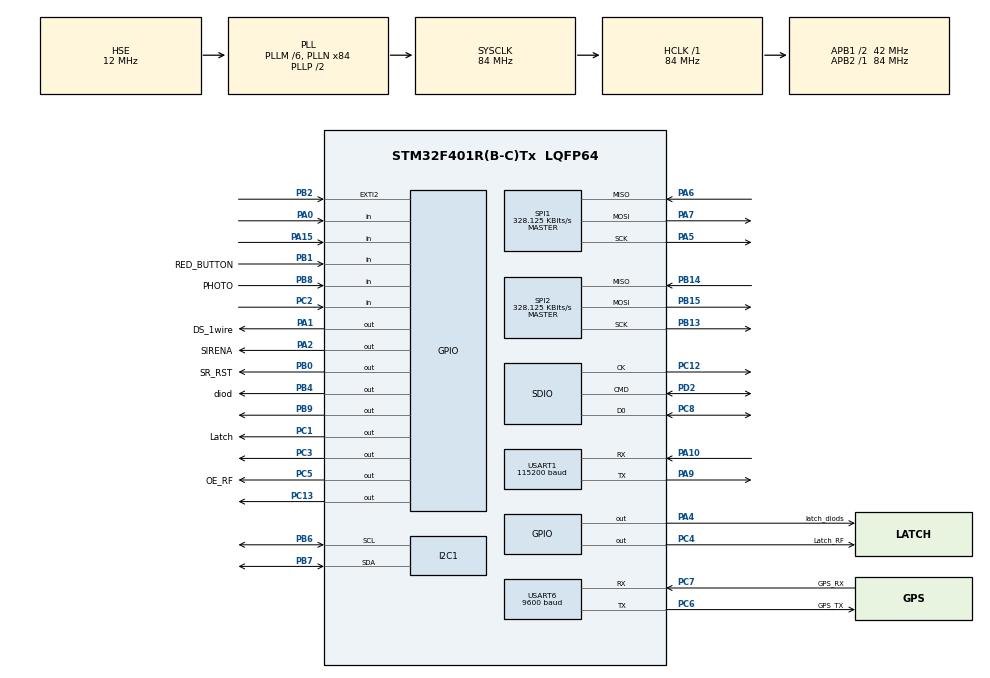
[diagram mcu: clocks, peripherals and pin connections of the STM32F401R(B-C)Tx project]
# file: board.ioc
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FATFS.BSP.number=1
FATFS._FS_LOCK=5
FATFS._USE_LFN=1
FATFS0.BSP.STBoard=false
FATFS0.BSP.api=Unknown
FATFS0.BSP.instance=PA15
FATFS0.BSP.ip=GPIO
FATFS0.BSP.mode=Input
FATFS0.BSP.name=Detect_SDIO
FATFS0.BSP.solution=PA15
Mcu.Family=STM32F4
Mcu.Name=STM32F401R(B-C)Tx
Mcu.Package=LQFP64
NVIC.PriorityGroup=NVIC_PRIORITYGROUP_4
NVIC.USART6_IRQn=true\:0\:0\:false\:false\:true\:true\:true\:true
PA0-WKUP.Signal=GPIO_Input
PA1.GPIO_Label=DS_1wire
PA1.Signal=GPIO_Output
PA10.Mode=Asynchronous
PA10.Signal=USART1_RX
PA13.Mode=Serial_Wire
PA13.Signal=SYS_JTMS-SWDIO
PA14.Mode=Serial_Wire
PA14.Signal=SYS_JTCK-SWCLK
PA15.GPIO_PuPd=GPIO_PULLUP
PA15.Signal=GPIO_Input
PA2.GPIO_Label=SIRENA
PA2.Signal=GPIO_Output
PA4.GPIO_Label=latch_diods
PA4.Signal=GPIO_Output
PA5.Mode=Full_Duplex_Master
PA5.Signal=SPI1_SCK
PA6.Mode=Full_Duplex_Master
PA6.Signal=SPI1_MISO
PA7.Mode=Full_Duplex_Master
PA7.Signal=SPI1_MOSI
PA9.Mode=Asynchronous
PA9.Signal=USART1_TX
PB0.GPIO_Label=SR_RST
PB0.PinState=GPIO_PIN_SET
PB0.Signal=GPIO_Output
PB1.GPIO_Label=RED_BUTTON
PB1.GPIO_PuPd=GPIO_PULLUP
PB1.Signal=GPIO_Input
PB13.Mode=Full_Duplex_Master
PB13.Signal=SPI2_SCK
PB14.Mode=Full_Duplex_Master
PB14.Signal=SPI2_MISO
PB15.Mode=Full_Duplex_Master
PB15.Signal=SPI2_MOSI
PB2.Signal=GPXTI2
PB4.GPIO_Label=diod
PB4.Signal=GPIO_Output
PB6.Mode=I2C
PB6.Signal=I2C1_SCL
PB7.Mode=I2C
PB7.Signal=I2C1_SDA
PB8.GPIO_Label=PHOTO
PB8.Signal=GPIO_Input
PB9.Signal=GPIO_Output
PC1.GPIO_Label=Latch
PC1.Signal=GPIO_Output
PC12.Mode=SD_1_bit
PC12.Signal=SDIO_CK
PC13-ANTI_TAMP.Signal=GPIO_Output
PC2.Signal=GPIO_Input
PC3.GPIO_ModeDefaultOutputPP=GPIO_MODE_OUTPUT_PP
PC3.GPIO_PuPd=GPIO_NOPULL
PC3.PinState=GPIO_PIN_SET
PC3.Signal=GPIO_Output
PC4.GPIO_Label=Latch_RF
PC4.Signal=GPIO_Output
PC5.GPIO_Label=OE_RF
PC5.Signal=GPIO_Output
PC6.GPIO_Label=GPS_TX
PC6.Mode=Asynchronous
PC6.Signal=USART6_TX
PC7.GPIO_Label=GPS_RX
PC7.Mode=Asynchronous
PC7.Signal=USART6_RX
PC8.Mode=SD_1_bit
PC8.Signal=SDIO_D0
PD2.Mode=SD_1_bit
PD2.Signal=SDIO_CMD
PH0\ -\ OSC_IN.Mode=HSE-External-Oscillator
PH0\ -\ OSC_IN.Signal=RCC_OSC_IN
PH1\ -\ OSC_OUT.Mode=HSE-External-Oscillator
PH1\ -\ OSC_OUT.Signal=RCC_OSC_OUT
ProjectManager.HeapSize=0x200
ProjectManager.StackSize=0x400
ProjectManager.TargetToolchain=STM32CubeIDE
RCC.48MHZClocksFreq_Value=42000000
RCC.AHBFreq_Value=84000000
RCC.APB1CLKDivider=RCC_HCLK_DIV2
RCC.APB1Freq_Value=42000000
RCC.APB1TimFreq_Value=84000000
RCC.APB2Freq_Value=84000000
RCC.APB2TimFreq_Value=84000000
RCC.CortexFreq_Value=84000000
RCC.HCLKFreq_Value=84000000
RCC.HSE_VALUE=12000000
RCC.HSI_VALUE=16000000
RCC.LSE_VALUE=32768
RCC.PLLM=6
RCC.PLLN=84
RCC.PLLSourceVirtual=RCC_PLLSOURCE_HSE
RCC.SYSCLKFreq_VALUE=84000000
RCC.SYSCLKSource=RCC_SYSCLKSOURCE_PLLCLK
RCC.VCOOutputFreq_Value=168000000
SDIO.ClockDiv=10
SPI1.BaudRatePrescaler=SPI_BAUDRATEPRESCALER_256
SPI1.CLKPolarity=SPI_POLARITY_LOW
SPI1.CalculateBaudRate=328.125 KBits/s
SPI1.Direction=SPI_DIRECTION_2LINES
SPI1.Mode=SPI_MODE_MASTER
SPI1.VirtualType=VM_MASTER
SPI2.BaudRatePrescaler=SPI_BAUDRATEPRESCALER_128
SPI2.CalculateBaudRate=328.125 KBits/s
SPI2.Direction=SPI_DIRECTION_2LINES
SPI2.Mode=SPI_MODE_MASTER
SPI2.VirtualType=VM_MASTER
USART1.BaudRate=115200
USART1.VirtualMode=VM_ASYNC
USART6.BaudRate=9600
USART6.VirtualMode=VM_ASYNC
VP_FATFS_VS_SDIO.Mode=SDIO
board=custom

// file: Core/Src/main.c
/* USER CODE BEGIN Header */
/**
  ******************************************************************************
  * @file           : main.c
  * @brief          : Main program body
  ******************************************************************************
  * @attention
  *
  * Copyright (c) 2023 STMicroelectronics.
  * All rights reserved.
  *
  * This software is licensed under terms that can be found in the LICENSE file
  * in the root directory of this software component.
  * If no LICENSE file comes with this software, it is provided AS-IS.
  *
  ******************************************************************************
  */
/* USER CODE END Header */
#include "main.h"
#include "fatfs.h"

/* USER CODE BEGIN PTD */
//int app_main(void);
/* USER CODE END PTD */

I2C_HandleTypeDef hi2c1;

SD_HandleTypeDef hsd;

SPI_HandleTypeDef hspi1;
SPI_HandleTypeDef hspi2;

UART_HandleTypeDef huart1;
UART_HandleTypeDef huart6;

void SystemClock_Config(void);
static void MX_GPIO_Init(void);
static void MX_I2C1_Init(void);
static void MX_SPI2_Init(void);
static void MX_USART1_UART_Init(void);
static void MX_USART6_UART_Init(void);
static void MX_SPI1_Init(void);
static void MX_SDIO_SD_Init(void);
/* USER CODE BEGIN PFP */
void app_main(void);
/* USER CODE END PFP */

int main(void)
{

  /* MCU Configuration--------------------------------------------------------*/

  /* Reset of all peripherals, Initializes the Flash interface and the Systick. */
  HAL_Init();

  /* Configure the system clock */
  SystemClock_Config();

  /* Initialize all configured peripherals */
  MX_GPIO_Init();
  MX_I2C1_Init();
  MX_SPI2_Init();
  MX_USART1_UART_Init();
  MX_USART6_UART_Init();
  MX_SPI1_Init();
  MX_SDIO_SD_Init();
  MX_FATFS_Init();
  /* USER CODE BEGIN 2 */
  app_main();
  /* USER CODE END 2 */

  /* Infinite loop */
  while (1)
  {

  }
}

void SystemClock_Config(void)
{
  RCC_OscInitTypeDef RCC_OscInitStruct = {0};
  RCC_ClkInitTypeDef RCC_ClkInitStruct = {0};

  /** Configure the main internal regulator output voltage
  */
  __HAL_RCC_PWR_CLK_ENABLE();
  __HAL_PWR_VOLTAGESCALING_CONFIG(PWR_REGULATOR_VOLTAGE_SCALE2);

  /** Initializes the RCC Oscillators according to the specified parameters
  * in the RCC_OscInitTypeDef structure.
  */
  RCC_OscInitStruct.OscillatorType = RCC_OSCILLATORTYPE_HSE;
  RCC_OscInitStruct.HSEState = RCC_HSE_ON;
  RCC_OscInitStruct.PLL.PLLState = RCC_PLL_ON;
  RCC_OscInitStruct.PLL.PLLSource = RCC_PLLSOURCE_HSE;
  RCC_OscInitStruct.PLL.PLLM = 6;
  RCC_OscInitStruct.PLL.PLLN = 84;
  RCC_OscInitStruct.PLL.PLLP = RCC_PLLP_DIV2;
  RCC_OscInitStruct.PLL.PLLQ = 4;
  if (HAL_RCC_OscConfig(&RCC_OscInitStruct) != HAL_OK)
  {
    Error_Handler();
  }

  /** Initializes the CPU, AHB and APB buses clocks
  */
  RCC_ClkInitStruct.ClockType = RCC_CLOCKTYPE_HCLK|RCC_CLOCKTYPE_SYSCLK
                              |RCC_CLOCKTYPE_PCLK1|RCC_CLOCKTYPE_PCLK2;
  RCC_ClkInitStruct.SYSCLKSource = RCC_SYSCLKSOURCE_PLLCLK;
  RCC_ClkInitStruct.AHBCLKDivider = RCC_SYSCLK_DIV1;
  RCC_ClkInitStruct.APB1CLKDivider = RCC_HCLK_DIV2;
  RCC_ClkInitStruct.APB2CLKDivider = RCC_HCLK_DIV1;

  if (HAL_RCC_ClockConfig(&RCC_ClkInitStruct, FLASH_LATENCY_2) != HAL_OK)
  {
    Error_Handler();
  }
}

static void MX_I2C1_Init(void)
{

  hi2c1.Instance = I2C1;
  hi2c1.Init.ClockSpeed = 100000;
  hi2c1.Init.DutyCycle = I2C_DUTYCYCLE_2;
  hi2c1.Init.OwnAddress1 = 0;
  hi2c1.Init.AddressingMode = I2C_ADDRESSINGMODE_7BIT;
  hi2c1.Init.DualAddressMode = I2C_DUALADDRESS_DISABLE;
  hi2c1.Init.OwnAddress2 = 0;
  hi2c1.Init.GeneralCallMode = I2C_GENERALCALL_DISABLE;
  hi2c1.Init.NoStretchMode = I2C_NOSTRETCH_DISABLE;
  if (HAL_I2C_Init(&hi2c1) != HAL_OK)
  {
    Error_Handler();
  }

}

static void MX_SDIO_SD_Init(void)
{

  hsd.Instance = SDIO;
  hsd.Init.ClockEdge = SDIO_CLOCK_EDGE_RISING;
  hsd.Init.ClockBypass = SDIO_CLOCK_BYPASS_DISABLE;
  hsd.Init.ClockPowerSave = SDIO_CLOCK_POWER_SAVE_DISABLE;
  hsd.Init.BusWide = SDIO_BUS_WIDE_1B;
  hsd.Init.HardwareFlowControl = SDIO_HARDWARE_FLOW_CONTROL_DISABLE;
  hsd.Init.ClockDiv = 10;

}

static void MX_SPI1_Init(void)
{

  /* SPI1 parameter configuration*/
  hspi1.Instance = SPI1;
  hspi1.Init.Mode = SPI_MODE_MASTER;
  hspi1.Init.Direction = SPI_DIRECTION_2LINES;
  hspi1.Init.DataSize = SPI_DATASIZE_8BIT;
  hspi1.Init.CLKPolarity = SPI_POLARITY_LOW;
  hspi1.Init.CLKPhase = SPI_PHASE_1EDGE;
  hspi1.Init.NSS = SPI_NSS_SOFT;
  hspi1.Init.BaudRatePrescaler = SPI_BAUDRATEPRESCALER_256;
  hspi1.Init.FirstBit = SPI_FIRSTBIT_MSB;
  hspi1.Init.TIMode = SPI_TIMODE_DISABLE;
  hspi1.Init.CRCCalculation = SPI_CRCCALCULATION_DISABLE;
  hspi1.Init.CRCPolynomial = 10;
  if (HAL_SPI_Init(&hspi1) != HAL_OK)
  {
    Error_Handler();
  }

}

static void MX_SPI2_Init(void)
{

  /* SPI2 parameter configuration*/
  hspi2.Instance = SPI2;
  hspi2.Init.Mode = SPI_MODE_MASTER;
  hspi2.Init.Direction = SPI_DIRECTION_2LINES;
  hspi2.Init.DataSize = SPI_DATASIZE_8BIT;
  hspi2.Init.CLKPolarity = SPI_POLARITY_LOW;
  hspi2.Init.CLKPhase = SPI_PHASE_1EDGE;
  hspi2.Init.NSS = SPI_NSS_SOFT;
  hspi2.Init.BaudRatePrescaler = SPI_BAUDRATEPRESCALER_128;
  hspi2.Init.FirstBit = SPI_FIRSTBIT_MSB;
  hspi2.Init.TIMode = SPI_TIMODE_DISABLE;
  hspi2.Init.CRCCalculation = SPI_CRCCALCULATION_DISABLE;
  hspi2.Init.CRCPolynomial = 10;
  if (HAL_SPI_Init(&hspi2) != HAL_OK)
  {
    Error_Handler();
  }

}

static void MX_USART1_UART_Init(void)
{

  huart1.Instance = USART1;
  huart1.Init.BaudRate = 115200;
  huart1.Init.WordLength = UART_WORDLENGTH_8B;
  huart1.Init.StopBits = UART_STOPBITS_1;
  huart1.Init.Parity = UART_PARITY_NONE;
  huart1.Init.Mode = UART_MODE_TX_RX;
  huart1.Init.HwFlowCtl = UART_HWCONTROL_NONE;
  huart1.Init.OverSampling = UART_OVERSAMPLING_16;
  if (HAL_UART_Init(&huart1) != HAL_OK)
  {
    Error_Handler();
  }

}

static void MX_USART6_UART_Init(void)
{

  huart6.Instance = USART6;
  huart6.Init.BaudRate = 9600;
  huart6.Init.WordLength = UART_WORDLENGTH_8B;
  huart6.Init.StopBits = UART_STOPBITS_1;
  huart6.Init.Parity = UART_PARITY_NONE;
  huart6.Init.Mode = UART_MODE_TX_RX;
  huart6.Init.HwFlowCtl = UART_HWCONTROL_NONE;
  huart6.Init.OverSampling = UART_OVERSAMPLING_16;
  if (HAL_UART_Init(&huart6) != HAL_OK)
  {
    Error_Handler();
  }

}

static void MX_GPIO_Init(void)
{
  GPIO_InitTypeDef GPIO_InitStruct = {0};

  /* GPIO Ports Clock Enable */
  __HAL_RCC_GPIOC_CLK_ENABLE();
  __HAL_RCC_GPIOH_CLK_ENABLE();
  __HAL_RCC_GPIOA_CLK_ENABLE();
  __HAL_RCC_GPIOB_CLK_ENABLE();
  __HAL_RCC_GPIOD_CLK_ENABLE();

  /*Configure GPIO pin Output Level */
  HAL_GPIO_WritePin(GPIOC, GPIO_PIN_13|Latch_Pin|Latch_RF_Pin|OE_RF_Pin, GPIO_PIN_RESET);

  /*Configure GPIO pin Output Level */
  HAL_GPIO_WritePin(GPIOC, GPIO_PIN_3, GPIO_PIN_SET);

  /*Configure GPIO pin Output Level */
  HAL_GPIO_WritePin(GPIOA, DS_1wire_Pin|SIRENA_Pin|latch_diods_Pin, GPIO_PIN_RESET);

  /*Configure GPIO pin Output Level */
  HAL_GPIO_WritePin(SR_RST_GPIO_Port, SR_RST_Pin, GPIO_PIN_SET);

  /*Configure GPIO pin Output Level */
  HAL_GPIO_WritePin(GPIOB, diod_Pin|GPIO_PIN_9, GPIO_PIN_RESET);

  /*Configure GPIO pins : PC13 Latch_Pin PC3 Latch_RF_Pin
                           OE_RF_Pin */
  GPIO_InitStruct.Pin = GPIO_PIN_13|Latch_Pin|GPIO_PIN_3|Latch_RF_Pin
                          |OE_RF_Pin;
  GPIO_InitStruct.Mode = GPIO_MODE_OUTPUT_PP;
  GPIO_InitStruct.Pull = GPIO_NOPULL;
  GPIO_InitStruct.Speed = GPIO_SPEED_FREQ_LOW;
  HAL_GPIO_Init(GPIOC, &GPIO_InitStruct);

  /*Configure GPIO pin : PC2 */
  GPIO_InitStruct.Pin = GPIO_PIN_2;
  GPIO_InitStruct.Mode = GPIO_MODE_INPUT;
  GPIO_InitStruct.Pull = GPIO_NOPULL;
  HAL_GPIO_Init(GPIOC, &GPIO_InitStruct);

  /*Configure GPIO pin : PA0 */
  GPIO_InitStruct.Pin = GPIO_PIN_0;
  GPIO_InitStruct.Mode = GPIO_MODE_INPUT;
  GPIO_InitStruct.Pull = GPIO_NOPULL;
  HAL_GPIO_Init(GPIOA, &GPIO_InitStruct);

  /*Configure GPIO pins : DS_1wire_Pin SIRENA_Pin latch_diods_Pin */
  GPIO_InitStruct.Pin = DS_1wire_Pin|SIRENA_Pin|latch_diods_Pin;
  GPIO_InitStruct.Mode = GPIO_MODE_OUTPUT_PP;
  GPIO_InitStruct.Pull = GPIO_NOPULL;
  GPIO_InitStruct.Speed = GPIO_SPEED_FREQ_LOW;
  HAL_GPIO_Init(GPIOA, &GPIO_InitStruct);

  /*Configure GPIO pins : SR_RST_Pin diod_Pin PB9 */
  GPIO_InitStruct.Pin = SR_RST_Pin|diod_Pin|GPIO_PIN_9;
  GPIO_InitStruct.Mode = GPIO_MODE_OUTPUT_PP;
  GPIO_InitStruct.Pull = GPIO_NOPULL;
  GPIO_InitStruct.Speed = GPIO_SPEED_FREQ_LOW;
  HAL_GPIO_Init(GPIOB, &GPIO_InitStruct);

  /*Configure GPIO pin : RED_BUTTON_Pin */
  GPIO_InitStruct.Pin = RED_BUTTON_Pin;
  GPIO_InitStruct.Mode = GPIO_MODE_INPUT;
  GPIO_InitStruct.Pull = GPIO_PULLUP;
  HAL_GPIO_Init(RED_BUTTON_GPIO_Port, &GPIO_InitStruct);

  /*Configure GPIO pin : PB2 */
  GPIO_InitStruct.Pin = GPIO_PIN_2;
  GPIO_InitStruct.Mode = GPIO_MODE_IT_RISING;
  GPIO_InitStruct.Pull = GPIO_NOPULL;
  HAL_GPIO_Init(GPIOB, &GPIO_InitStruct);

  /*Configure GPIO pin : PA15 */
  GPIO_InitStruct.Pin = GPIO_PIN_15;
  GPIO_InitStruct.Mode = GPIO_MODE_INPUT;
  GPIO_InitStruct.Pull = GPIO_PULLUP;
  HAL_GPIO_Init(GPIOA, &GPIO_InitStruct);

  /*Configure GPIO pin : PHOTO_Pin */
  GPIO_InitStruct.Pin = PHOTO_Pin;
  GPIO_InitStruct.Mode = GPIO_MODE_INPUT;
  GPIO_InitStruct.Pull = GPIO_NOPULL;
  HAL_GPIO_Init(PHOTO_GPIO_Port, &GPIO_InitStruct);

}

void Error_Handler(void)
{
  __disable_irq();
  while (1)
  {
  }
}
